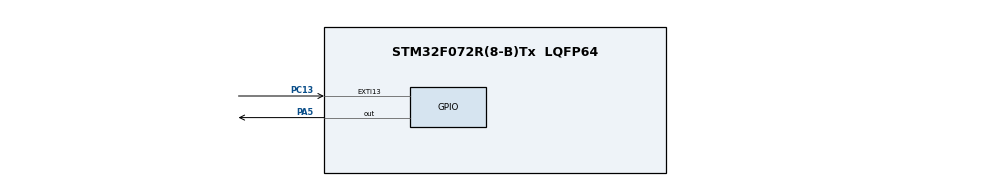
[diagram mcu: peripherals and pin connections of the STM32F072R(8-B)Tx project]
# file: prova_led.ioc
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Mcu.Family=STM32F0
Mcu.Name=STM32F072R(8-B)Tx
Mcu.Package=LQFP64
NVIC.EXTI4_15_IRQn=true\:0\:0\:false\:false\:true\:true\:true
NVIC.TIM7_IRQn=true\:0\:0\:false\:false\:true\:true\:true
PA5.Signal=GPIO_Output
PC13.Signal=GPXTI13
ProjectManager.HeapSize=0x200
ProjectManager.StackSize=0x400
ProjectManager.TargetToolchain=MDK-ARM V5.27
TIM7.Period=10000
TIM7.Prescaler=1
VP_TIM7_VS_ClockSourceINT.Mode=Enable_Timer
board=custom

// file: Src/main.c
/* USER CODE BEGIN Header */
/**
  ******************************************************************************
  * @file           : main.c
  * @brief          : Main program body
  ******************************************************************************
  * @attention
  *
  * <h2><center>&copy; Copyright (c) 2019 STMicroelectronics.
  * All rights reserved.</center></h2>
  *
  * This software component is licensed by ST under BSD 3-Clause license,
  * the "License"; You may not use this file except in compliance with the
  * License. You may obtain a copy of the License at:
  *                        opensource.org/licenses/BSD-3-Clause
  *
  ******************************************************************************
  */
/* USER CODE END Header */

#include "main.h"

/* USER CODE BEGIN Includes */
extern int loops_on;
extern int n_loops;
extern int acceso;
extern int wait;
extern int loops;
/* USER CODE END Includes */

/* USER CODE BEGIN PTD */
void wait_tim(){
	wait=1;
	TIM7->CNT=0;
	TIM7->SR=0;
	TIM7->CR1|=TIM_CR1_CEN;
	while(wait){}
}
/* USER CODE END PTD */

TIM_HandleTypeDef htim7;

void SystemClock_Config(void);
static void MX_GPIO_Init(void);
static void MX_TIM7_Init(void);

int main(void)
{
  /* USER CODE BEGIN 1 */
	acceso=0;
  /* USER CODE END 1 */

  /* MCU Configuration--------------------------------------------------------*/

  /* Reset of all peripherals, Initializes the Flash interface and the Systick. */
  HAL_Init();

  /* Configure the system clock */
  SystemClock_Config();

  /* Initialize all configured peripherals */
  MX_GPIO_Init();
  MX_TIM7_Init();
  /* USER CODE BEGIN 2 */
	//attivo l'interrupt per il timer
	//loops=10;
	TIM7->DIER|=TIM_DIER_UIE;
  /* USER CODE END 2 */

  /* Infinite loop */
  /* USER CODE BEGIN WHILE */
	/*
	int i=0;
	while(i<100){
		while(TIM7->SR==0){}
		i++;
	}*/
  while (1)
  {
		if(acceso==0){
			//accendo
			HAL_GPIO_TogglePin(GPIOA,GPIO_PIN_5);
			//HAL_Delay(loops_on);
			//devo aspettare loops_on cicli
			loops=loops_on;
			wait_tim();
			acceso=1;
		}
		else{
			//spengo
			HAL_GPIO_TogglePin(GPIOA,GPIO_PIN_5);
			//HAL_Delay(n_loops-loops_on);
			loops=n_loops-loops_on;
			wait_tim();
			acceso=0;
		}
    /* USER CODE END WHILE */

  }
}

void SystemClock_Config(void)
{
  RCC_OscInitTypeDef RCC_OscInitStruct = {0};
  RCC_ClkInitTypeDef RCC_ClkInitStruct = {0};

  /** Initializes the CPU, AHB and APB busses clocks
  */
  RCC_OscInitStruct.OscillatorType = RCC_OSCILLATORTYPE_HSI;
  RCC_OscInitStruct.HSIState = RCC_HSI_ON;
  RCC_OscInitStruct.HSICalibrationValue = RCC_HSICALIBRATION_DEFAULT;
  RCC_OscInitStruct.PLL.PLLState = RCC_PLL_NONE;
  if (HAL_RCC_OscConfig(&RCC_OscInitStruct) != HAL_OK)
  {
    Error_Handler();
  }
  /** Initializes the CPU, AHB and APB busses clocks
  */
  RCC_ClkInitStruct.ClockType = RCC_CLOCKTYPE_HCLK|RCC_CLOCKTYPE_SYSCLK
                              |RCC_CLOCKTYPE_PCLK1;
  RCC_ClkInitStruct.SYSCLKSource = RCC_SYSCLKSOURCE_HSI;
  RCC_ClkInitStruct.AHBCLKDivider = RCC_SYSCLK_DIV1;
  RCC_ClkInitStruct.APB1CLKDivider = RCC_HCLK_DIV1;

  if (HAL_RCC_ClockConfig(&RCC_ClkInitStruct, FLASH_LATENCY_0) != HAL_OK)
  {
    Error_Handler();
  }
}

static void MX_TIM7_Init(void)
{

  TIM_MasterConfigTypeDef sMasterConfig = {0};

  htim7.Instance = TIM7;
  htim7.Init.Prescaler = 1;
  htim7.Init.CounterMode = TIM_COUNTERMODE_UP;
  htim7.Init.Period = 10000;
  htim7.Init.AutoReloadPreload = TIM_AUTORELOAD_PRELOAD_DISABLE;
  if (HAL_TIM_Base_Init(&htim7) != HAL_OK)
  {
    Error_Handler();
  }
  sMasterConfig.MasterOutputTrigger = TIM_TRGO_RESET;
  sMasterConfig.MasterSlaveMode = TIM_MASTERSLAVEMODE_DISABLE;
  if (HAL_TIMEx_MasterConfigSynchronization(&htim7, &sMasterConfig) != HAL_OK)
  {
    Error_Handler();
  }

}

static void MX_GPIO_Init(void)
{
  GPIO_InitTypeDef GPIO_InitStruct = {0};

  /* GPIO Ports Clock Enable */
  __HAL_RCC_GPIOC_CLK_ENABLE();
  __HAL_RCC_GPIOA_CLK_ENABLE();

  /*Configure GPIO pin Output Level */
  HAL_GPIO_WritePin(GPIOA, GPIO_PIN_5, GPIO_PIN_RESET);

  /*Configure GPIO pin : PC13 */
  GPIO_InitStruct.Pin = GPIO_PIN_13;
  GPIO_InitStruct.Mode = GPIO_MODE_IT_RISING;
  GPIO_InitStruct.Pull = GPIO_NOPULL;
  HAL_GPIO_Init(GPIOC, &GPIO_InitStruct);

  /*Configure GPIO pin : PA5 */
  GPIO_InitStruct.Pin = GPIO_PIN_5;
  GPIO_InitStruct.Mode = GPIO_MODE_OUTPUT_PP;
  GPIO_InitStruct.Pull = GPIO_NOPULL;
  GPIO_InitStruct.Speed = GPIO_SPEED_FREQ_LOW;
  HAL_GPIO_Init(GPIOA, &GPIO_InitStruct);

  /* EXTI interrupt init*/
  HAL_NVIC_SetPriority(EXTI4_15_IRQn, 0, 0);
  HAL_NVIC_EnableIRQ(EXTI4_15_IRQn);

}

void Error_Handler(void)
{
}

/************************ (C) COPYRIGHT STMicroelectronics *****END OF FILE****/
